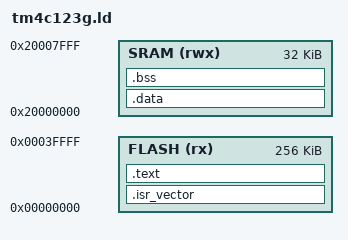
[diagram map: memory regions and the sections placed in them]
/* Minimal linker script for TM4C123G (Tiva C) */
MEMORY
{
  FLASH (rx) : ORIGIN = 0x00000000, LENGTH = 256K
  SRAM (rwx) : ORIGIN = 0x20000000, LENGTH = 32K
}

SECTIONS
{
  .isr_vector :
  {
    KEEP(*(.isr_vector))
  } > FLASH

  .text :
  {
    *(.text*)
    *(.rodata*)
  } > FLASH

  .data : AT (ADDR(.text) + SIZEOF(.text))
  {
    *(.data*)
  } > SRAM

  .bss :
  {
    *(.bss*)
    *(COMMON)
  } > SRAM
} 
